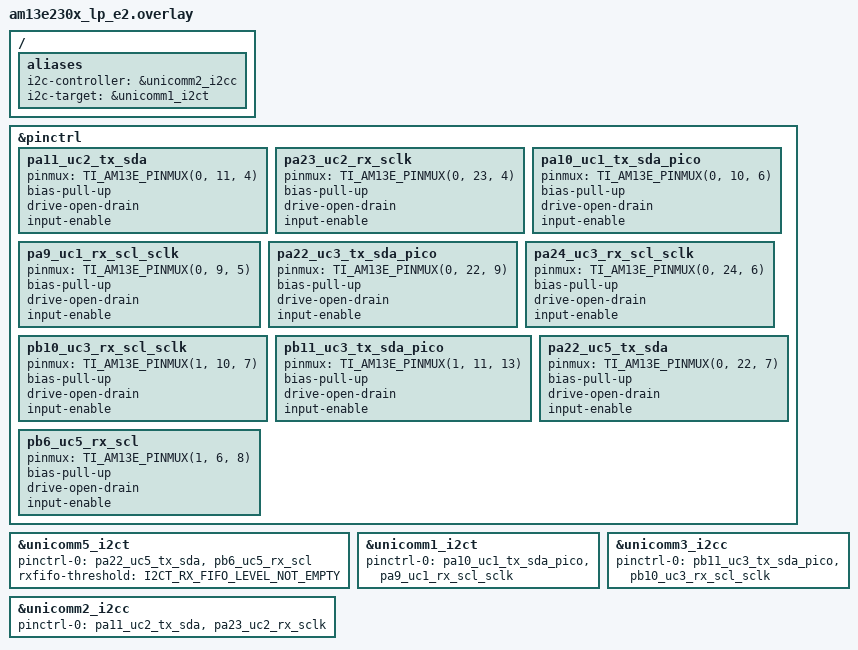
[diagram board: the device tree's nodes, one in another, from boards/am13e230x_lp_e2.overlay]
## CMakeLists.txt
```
# SPDX-License-Identifier: Apache-2.0

cmake_minimum_required(VERSION 3.20.0)

find_package(Zephyr REQUIRED HINTS $ENV{ZEPHYR_BASE})
project(i2c_loopback_test)

target_sources(app PRIVATE src/main.c)
```

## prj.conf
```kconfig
CONFIG_SERIAL=y
CONFIG_CONSOLE=y
CONFIG_UART_CONSOLE=y

CONFIG_I2C=y
CONFIG_I2C_TARGET=y

CONFIG_COMPILER_SAVE_TEMPS=y

CONFIG_LOG=y
CONFIG_LOG_BACKEND_UART=y
```

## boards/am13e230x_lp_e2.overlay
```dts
#include <zephyr/dt-bindings/i2c/ti-unicomm-i2c.h>

&pinctrl {
    pa11_uc2_tx_sda: pa11_uc2_tx_sda {
        pinmux = <TI_AM13E_PINMUX(0, 11, 4)>;
        bias-pull-up;
        drive-open-drain;    /* Matches DL_GPIO_enableHiZ */
        input-enable;        /* Required for bidirectional I2C */
    };

    pa23_uc2_rx_sclk: pa23_uc2_rx_sclk {
        pinmux = <TI_AM13E_PINMUX(0, 23, 4)>;
        bias-pull-up;
        drive-open-drain;
        input-enable;
    };

    /* Apply similar logic to your Target pins */
    pa10_uc1_tx_sda_pico: pa10_uc1_tx_sda_pico {
        pinmux = <TI_AM13E_PINMUX(0, 10, 6)>;
        bias-pull-up;
        drive-open-drain;
        input-enable;
    };

    pa9_uc1_rx_scl_sclk: pa9_uc1_rx_scl_sclk {
        pinmux = <TI_AM13E_PINMUX(0, 9, 5)>;
        bias-pull-up;
        drive-open-drain;
        input-enable;
    };

	/* non-advanced controller */
	pa22_uc3_tx_sda_pico: pa22_uc3_tx_sda_pico {
		pinmux = <TI_AM13E_PINMUX(0, 22, 9)>;
        bias-pull-up;
        drive-open-drain;
        input-enable;
	};

	pa24_uc3_rx_scl_sclk: pa24_uc3_rx_scl_sclk {
		pinmux = <TI_AM13E_PINMUX(0, 24, 6)>;
        bias-pull-up;
        drive-open-drain;
        input-enable;
	};

	pb10_uc3_rx_scl_sclk: pb10_uc3_rx_scl_sclk {
		pinmux = <TI_AM13E_PINMUX(1, 10, 7)>;
        bias-pull-up;
        drive-open-drain;
        input-enable;
	};

	pb11_uc3_tx_sda_pico: pb11_uc3_tx_sda_pico {
		pinmux = <TI_AM13E_PINMUX(1, 11, 13)>;
        bias-pull-up;
        drive-open-drain;
        input-enable;
	};

	/* advanced target */
	pa22_uc5_tx_sda: pa22_uc5_tx_sda {
		pinmux = <TI_AM13E_PINMUX(0, 22, 7)>;
        bias-pull-up;
        drive-open-drain;
        input-enable;
	};

	pb6_uc5_rx_scl: pb6_uc5_rx_scl {
		pinmux = <TI_AM13E_PINMUX(1, 6, 8)>;
        bias-pull-up;
        drive-open-drain;
        input-enable;
	};
};

/ {
	aliases {
		i2c-controller = &unicomm2_i2cc;
		i2c-target = &unicomm1_i2ct;
	};
};

/* advanced target */
&unicomm5_i2ct {
	status = "okay";

	pinctrl-0 = <&pa22_uc5_tx_sda &pb6_uc5_rx_scl>;
	pinctrl-names = "default";

	rxfifo-threshold = <I2CT_RX_FIFO_LEVEL_NOT_EMPTY>;
};

/* target */
&unicomm1_i2ct {
	status = "okay";

	pinctrl-0 = <&pa10_uc1_tx_sda_pico &pa9_uc1_rx_scl_sclk>;
	pinctrl-names = "default";

	//rxfifo-threshold = <I2CT_RX_FIFO_LEVEL_NOT_EMPTY>;
};

/* advanced controller */
&unicomm2_i2cc {
	status = "okay";

	pinctrl-0 = <&pa11_uc2_tx_sda &pa23_uc2_rx_sclk>;
	pinctrl-names = "default";
};

/* controller */
&unicomm3_i2cc {
	status = "okay";

	pinctrl-0 = <&pb11_uc3_tx_sda_pico &pb10_uc3_rx_scl_sclk>;
	pinctrl-names = "default";
};
```

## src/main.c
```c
/*
 * Copyright (c) 2026 Texas Instruments Incorporated
 *
 * SPDX-License-Identifier: Apache-2.0
 */

#include <stdio.h>
#include <zephyr/kernel.h>
#include <zephyr/drivers/i2c.h>

#define TARGET_ADDR 0x50

static char i2c_buf[] = "ABCDEFGHIJKLMNOPQRSTUVWXYZ";

static const struct device *i2c_controller = DEVICE_DT_GET(DT_ALIAS(i2c_controller));
static const struct device *i2c_target = DEVICE_DT_GET(DT_ALIAS(i2c_target));

static char target_data[] = "01234567898765432123456789";
static int target_data_ptr = 0;

#define TARGET_RX_BUFLEN 40
static char target_rx_data[TARGET_RX_BUFLEN];
static int target_rx_data_len = 0;

static bool write_requested_send_nack = true;
static bool read_requested_send_nack = true;

int my_stop(struct i2c_target_config *config) {
	if (write_requested_send_nack) {
		write_requested_send_nack = false; // only do it once
		target_rx_data_len = 0;
	}

	if (read_requested_send_nack) {
		target_data_ptr = 0;
		read_requested_send_nack = false;
	}
	printk("\nmy_stop reached\n");
}

int my_write_requested(struct i2c_target_config *config) {
	if (write_requested_send_nack) {
		return -1; /* "An error return shall cause the controller to NACK the next byte received" */
	}
	return 0;
}

int my_write_received(struct i2c_target_config *config, uint8_t data) {
	if (target_rx_data_len == TARGET_RX_BUFLEN) target_rx_data_len = 0;

	target_rx_data[target_rx_data_len++] = data;

	return 0;
}

int my_read_requested(struct i2c_target_config *config, uint8_t *data) {
	if (read_requested_send_nack) {
		return -1;
	}

	if (target_data_ptr < sizeof(target_data)) {
		*data = target_data[target_data_ptr++];
	} else {
		*data = 0;
	}

	return 0;
}

int my_read_processed(struct i2c_target_config *config, uint8_t *data) {
	if (target_data_ptr < sizeof(target_data)) {
		*data = target_data[target_data_ptr++];
	} else {
		*data = 0;
	}

	return 0;
}

static const struct i2c_target_callbacks target_callbacks = {
	.write_requested = my_write_requested,
	.write_received = my_write_received,
	.read_requested = my_read_requested,
	.read_processed = my_read_processed,
	.stop = my_stop,
};

static struct i2c_target_config target_cfg = {
	.address = TARGET_ADDR,
	.callbacks = &target_callbacks,
	//.flags = I2C_TARGET_FLAGS_ADDR_10_BITS,
};

int main(void)
{
	//dl_target_init();

	struct i2c_msg tx = {
		.buf = i2c_buf,
		.len = sizeof(i2c_buf),
		.flags = I2C_MSG_WRITE | I2C_MSG_STOP,
		//.flags = I2C_MSG_READ | I2C_MSG_STOP,
	};

	if (i2c_target_register(i2c_target, &target_cfg) != 0) {
		printk("Error registering target\n");
	}

	if (i2c_configure(i2c_controller, I2C_MODE_CONTROLLER | I2C_SPEED_SET(I2C_SPEED_STANDARD)) != 0) {
		printk("Error configuring i2c speed\n");
	}

	int ret = i2c_transfer(i2c_controller, &tx, 1, TARGET_ADDR);

	if (tx.flags & I2C_MSG_READ) {
		printk("received bytes from target: ");
		for (int i=0; i<tx.len; i++) {
			printk("%c, ", tx.buf[i]);
		}
		printk("\n");
	} else {
		printk("received bytes into target: ");
		for (int i=0; i<target_rx_data_len; i++) {
			printk("%c, ", target_rx_data[i]);
		}
		printk("\n");
	}

	printk("tx i2c_transfer returned %d\n", ret);

	/*
	 * Second transfer
	 */
	if (i2c_configure(i2c_controller, I2C_MODE_CONTROLLER | I2C_SPEED_SET(I2C_SPEED_STANDARD)) != 0) {
		printk("Error reseting i2c controller\n");
	}
	ret = i2c_transfer(i2c_controller, &tx, 1, TARGET_ADDR);

	if (tx.flags & I2C_MSG_READ) {
		printk("received bytes from target: ");
		for (int i=0; i<tx.len; i++) {
			printk("%c, ", tx.buf[i]);
		}
		printk("\n");
	} else {
		printk("received bytes into target: ");
		for (int i=0; i<target_rx_data_len; i++) {
			printk("%c, ", target_rx_data[i]);
		}
		printk("\n");
	}

	printk("tx i2c_transfer returned %d\n", ret);

	return 0;
}
```

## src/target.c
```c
/*
 * Copyright (c) 2026 Texas Instruments Incorporated
 *
 * SPDX-License-Identifier: Apache-2.0
 */
#include <dl_unicommi2ct.h>
#include <dl_gpio.h>

/* Defines for APP_I2C_CONTROLLER */
#define APP_I2C_CONTROLLER_INST                                     UC2_INST_PTR
#define APP_I2C_CONTROLLER_BUS_SPEED_HZ                                   100000
#define GPIO_APP_I2C_CONTROLLER_SDA_PORT                                   GPIO0
#define GPIO_APP_I2C_CONTROLLER_SDA_PIN                           DL_GPIO_PIN_11
#define GPIO_APP_I2C_CONTROLLER_IOMUX_SDA                      (IOMUX_PINCM_PA11)
#define GPIO_APP_I2C_CONTROLLER_IOMUX_SDA_FUNC                   IOMUX_PA11_UC2_TX_SDA
#define GPIO_APP_I2C_CONTROLLER_SCL_PORT                                   GPIO0
#define GPIO_APP_I2C_CONTROLLER_SCL_PIN                           DL_GPIO_PIN_23
#define GPIO_APP_I2C_CONTROLLER_IOMUX_SCL                      (IOMUX_PINCM_PA23)
#define GPIO_APP_I2C_CONTROLLER_IOMUX_SCL_FUNC                   IOMUX_PA23_UC2_RX_SCL

/* Defines for APP_I2C_TARGET */
#define APP_I2C_TARGET_INST                                         UC1_INST_PTR
#define APP_I2C_TARGET_TARGET_OWN_ADDR                                      0x50
#define GPIO_APP_I2C_TARGET_SDA_PORT                                       GPIO0
#define GPIO_APP_I2C_TARGET_SDA_PIN                               DL_GPIO_PIN_10
#define GPIO_APP_I2C_TARGET_IOMUX_SDA                         (IOMUX_PINCM_PA10)
#define GPIO_APP_I2C_TARGET_IOMUX_SDA_FUNC              IOMUX_PA10_UC1_TX_SDA_PICO
#define GPIO_APP_I2C_TARGET_SCL_PORT                                       GPIO0
#define GPIO_APP_I2C_TARGET_SCL_PIN                                DL_GPIO_PIN_9
#define GPIO_APP_I2C_TARGET_IOMUX_SCL                          (IOMUX_PINCM_PA9)
#define GPIO_APP_I2C_TARGET_IOMUX_SCL_FUNC               IOMUX_PA9_UC1_RX_SCL_SCLK

void SYSCFG_DL_initPower(void)
{
    DL_GPIO_reset(GPIO0);
    DL_GPIO_reset(GPIO1);
    DL_GPIO_reset(GPIO2);
    DL_GPIO_reset(GPIO3);

    DL_I2CT_reset(APP_I2C_TARGET_INST);

    DL_GPIO_enablePower(GPIO0);
    DL_GPIO_enablePower(GPIO1);
    DL_GPIO_enablePower(GPIO2);
    DL_GPIO_enablePower(GPIO3);

    DL_I2CT_enablePower(APP_I2C_TARGET_INST);
}

void SYSCFG_DL_Pinmux_init(void)
{
    DL_GPIO_initPeripheralAnalogFunction(IOMUX_PINCM_PC16_X1);
    DL_GPIO_initPeripheralAnalogFunction(IOMUX_PINCM_PC17_X2);

	DL_GPIO_initPeripheralInputFunctionFeatures(
		 GPIO_APP_I2C_CONTROLLER_IOMUX_SDA, GPIO_APP_I2C_CONTROLLER_IOMUX_SDA_FUNC,
		 DL_GPIO_INVERSION_DISABLE, DL_GPIO_RESISTOR_PULL_UP,
		 DL_GPIO_HYSTERESIS_DISABLE, DL_GPIO_WAKEUP_DISABLE);
	DL_GPIO_initPeripheralInputFunctionFeatures(
		 GPIO_APP_I2C_CONTROLLER_IOMUX_SCL, GPIO_APP_I2C_CONTROLLER_IOMUX_SCL_FUNC,
		 DL_GPIO_INVERSION_DISABLE, DL_GPIO_RESISTOR_PULL_UP,
		 DL_GPIO_HYSTERESIS_DISABLE, DL_GPIO_WAKEUP_DISABLE);
    DL_GPIO_enableHiZ(GPIO_APP_I2C_CONTROLLER_IOMUX_SDA);
    DL_GPIO_enableHiZ(GPIO_APP_I2C_CONTROLLER_IOMUX_SCL);

	DL_GPIO_initPeripheralInputFunctionFeatures(
		 GPIO_APP_I2C_TARGET_IOMUX_SDA, GPIO_APP_I2C_TARGET_IOMUX_SDA_FUNC,
		 DL_GPIO_INVERSION_DISABLE, DL_GPIO_RESISTOR_PULL_UP,
		 DL_GPIO_HYSTERESIS_DISABLE, DL_GPIO_WAKEUP_DISABLE);
	DL_GPIO_initPeripheralInputFunctionFeatures(
		 GPIO_APP_I2C_TARGET_IOMUX_SCL, GPIO_APP_I2C_TARGET_IOMUX_SCL_FUNC,
		 DL_GPIO_INVERSION_DISABLE, DL_GPIO_RESISTOR_PULL_UP,
		 DL_GPIO_HYSTERESIS_DISABLE, DL_GPIO_WAKEUP_DISABLE);
    DL_GPIO_enableHiZ(GPIO_APP_I2C_TARGET_IOMUX_SDA);
    DL_GPIO_enableHiZ(GPIO_APP_I2C_TARGET_IOMUX_SCL);
}

static const DL_I2CT_ClockConfig gAPP_I2C_TARGETClockConfig = {
    .clockSel = DL_I2CT_CLOCK_BUSCLK,
    .divideRatio = DL_I2CT_CLOCK_DIVIDE_1,
};

void SYSCFG_DL_APP_I2C_TARGET_init(void) {
    DL_I2CT_setClockConfig(APP_I2C_TARGET_INST,
        (DL_I2CT_ClockConfig *) &gAPP_I2C_TARGETClockConfig);

    /* Configure Target Mode */
    DL_I2CT_setOwnAddress(APP_I2C_TARGET_INST, APP_I2C_TARGET_TARGET_OWN_ADDR);
    DL_I2CT_setTXFIFOThreshold(APP_I2C_TARGET_INST, DL_I2CT_TX_FIFO_LEVEL_1_2_EMPTY);
    DL_I2CT_setRXFIFOThreshold(APP_I2C_TARGET_INST, DL_I2CT_RX_FIFO_LEVEL_NOT_EMPTY);

    /* Clock stretching would deadlock when controller and target share a single
     * CPU with a blocking polling transfer — target can't drain its RX FIFO
     * while the controller is busy-waiting for SCL to be released. */
    DL_I2CT_disableClockStretching(APP_I2C_TARGET_INST);

    /* Enable module */
    DL_I2CT_enable(APP_I2C_TARGET_INST);
}

void dl_target_init(void)
{
    SYSCFG_DL_initPower();
    SYSCFG_DL_Pinmux_init();
    //SYSCFG_DL_APP_I2C_TARGET_init();
}

/* target I2C buffer */
static volatile char rx_buf[128];

static volatile char *rx_buf_ptr = rx_buf;
static volatile int rx_remaining_bytes = 26;

static volatile bool is_rx_complete = false;

void target_receive_bytes(void)
{
    while (!DL_I2CT_isRXFIFOEmpty(APP_I2C_TARGET_INST) && rx_remaining_bytes > 0U)
    {
        *rx_buf_ptr = DL_I2CT_receiveData(APP_I2C_TARGET_INST);
        rx_buf_ptr++;
        rx_remaining_bytes--;
    }

    /* Check for STOP or completion */

    bool isStopDetected = DL_I2CT_getRawInterruptStatus(APP_I2C_TARGET_INST, DL_I2CT_INTERRUPT_STOP);
    if (isStopDetected)
    {
        DL_I2CT_clearInterruptStatus(APP_I2C_TARGET_INST, DL_I2CT_INTERRUPT_STOP);
    }

    /* Transfer is complete if stop is detected or all bytes received */

    is_rx_complete = (isStopDetected && rx_remaining_bytes == 0U) || (rx_remaining_bytes == 0U);
}
```
